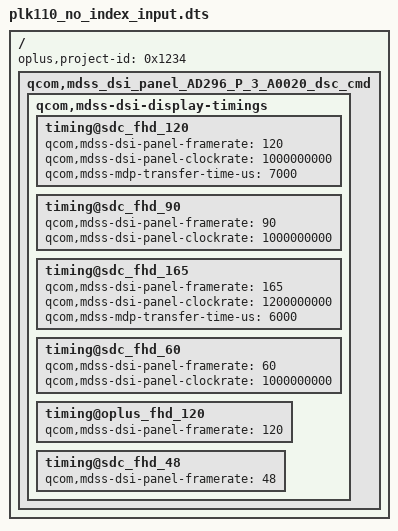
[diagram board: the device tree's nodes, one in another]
/dts-v1/;

/ {
	oplus,project-id = <0x1234>;

	qcom,mdss_dsi_panel_AD296_P_3_A0020_dsc_cmd {
		qcom,mdss-dsi-display-timings {
			timing@sdc_fhd_120 {
				qcom,mdss-dsi-panel-framerate = <120>;
				qcom,mdss-dsi-panel-clockrate = <1000000000>;
				qcom,mdss-mdp-transfer-time-us = <7000>;
			};
			timing@sdc_fhd_90 {
				qcom,mdss-dsi-panel-framerate = <90>;
				qcom,mdss-dsi-panel-clockrate = <1000000000>;
			};
			timing@sdc_fhd_165 {
				qcom,mdss-dsi-panel-framerate = <165>;
				qcom,mdss-dsi-panel-clockrate = <1200000000>;
				qcom,mdss-mdp-transfer-time-us = <6000>;
			};
			timing@sdc_fhd_60 {
				qcom,mdss-dsi-panel-framerate = <60>;
				qcom,mdss-dsi-panel-clockrate = <1000000000>;
			};
			timing@oplus_fhd_120 {
				qcom,mdss-dsi-panel-framerate = <120>;
			};
			timing@sdc_fhd_48 {
				qcom,mdss-dsi-panel-framerate = <48>;
			};
		};
	};
};
